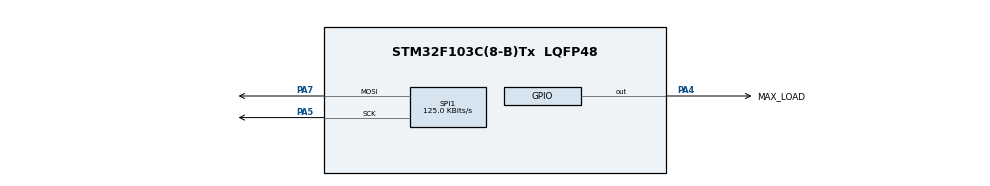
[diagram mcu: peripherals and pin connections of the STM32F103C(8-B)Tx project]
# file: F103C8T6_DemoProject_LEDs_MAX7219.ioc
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Mcu.Family=STM32F1
Mcu.Name=STM32F103C(8-B)Tx
Mcu.Package=LQFP48
NVIC.PriorityGroup=NVIC_PRIORITYGROUP_4
PA13.Mode=Serial_Wire
PA13.Signal=SYS_JTMS-SWDIO
PA14.Mode=Serial_Wire
PA14.Signal=SYS_JTCK-SWCLK
PA4.GPIO_Label=MAX_LOAD
PA4.Signal=GPIO_Output
PA5.Mode=TX_Only_Simplex_Unidirect_Master
PA5.Signal=SPI1_SCK
PA7.Mode=TX_Only_Simplex_Unidirect_Master
PA7.Signal=SPI1_MOSI
ProjectManager.HeapSize=0x200
ProjectManager.StackSize=0x400
ProjectManager.TargetToolchain=STM32CubeIDE
RCC.APB1Freq_Value=8000000
RCC.APB2Freq_Value=8000000
SPI1.BaudRatePrescaler=SPI_BAUDRATEPRESCALER_64
SPI1.CalculateBaudRate=125.0 KBits/s
SPI1.Direction=SPI_DIRECTION_2LINES
SPI1.Mode=SPI_MODE_MASTER
SPI1.VirtualType=VM_MASTER
board=custom

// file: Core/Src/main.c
/* USER CODE BEGIN Header */
/**
  ******************************************************************************
  * @file           : main.c
  * @brief          : Main program body
  ******************************************************************************
  * @attention
  *
  * Copyright (c) 2024 STMicroelectronics.
  * All rights reserved.
  *
  * This software is licensed under terms that can be found in the LICENSE file
  * in the root directory of this software component.
  * If no LICENSE file comes with this software, it is provided AS-IS.
  *
  ******************************************************************************
  */
/* USER CODE END Header */
#include "main.h"
#include "spi.h"
#include "gpio.h"

/* USER CODE BEGIN Includes */
#include "max7219.h"
#include <stdbool.h>
/* USER CODE END Includes */

/* USER CODE BEGIN PD */
#define NUM_LED_PER_ROW 8
/* USER CODE END PD */

/* USER CODE BEGIN PV */
max7219_TypeDef LedDriver;
max7219_LED_TypeDef LedRow1[NUM_LED_PER_ROW];
max7219_LED_TypeDef LedRow2[NUM_LED_PER_ROW];

uint8_t CounterLedsFx = 0;

bool ModeTurnOn = true;
/* USER CODE END PV */

void SystemClock_Config(void);

int main(void)
{

  /* MCU Configuration--------------------------------------------------------*/

  /* Reset of all peripherals, Initializes the Flash interface and the Systick. */
  HAL_Init();

  /* Configure the system clock */
  SystemClock_Config();

  /* Initialize all configured peripherals */
  MX_GPIO_Init();
  MX_SPI1_Init();
  /* USER CODE BEGIN 2 */
  max7219_init_SPI(&LedDriver, &hspi1);
  max7219_init_LoadPin(&LedDriver, GPIOA, GPIO_PIN_4);
  max7219_init_NoDecode(&LedDriver);

  for(uint8_t i = 0; i < NUM_LED_PER_ROW; i++)
  {
    uint8_t DigitRow1 = 0;
    uint8_t DigitRow2 = 1;
    max7219_init_LED(&LedRow1[i], DigitRow1, i);
    max7219_init_LED(&LedRow2[i], DigitRow2, i);
  }

  max7219_turnOff_AllLEDs(&LedDriver);
  /* USER CODE END 2 */

  /* Infinite loop */
  /* USER CODE BEGIN WHILE */
  while (1)
  {
    if(ModeTurnOn == true)
    {
      max7219_turnOn_LED(&LedDriver, &LedRow1[CounterLedsFx]);
      max7219_turnOn_LED(&LedDriver, &LedRow2[CounterLedsFx]);
    }
    else
    {
      max7219_turnOff_LED(&LedDriver, &LedRow1[CounterLedsFx]);
      max7219_turnOff_LED(&LedDriver, &LedRow2[CounterLedsFx]);
    }

    if(CounterLedsFx == (NUM_LED_PER_ROW - 1))
    {
      CounterLedsFx = 0;
      if(ModeTurnOn == true)
      {
        ModeTurnOn = false;
      }
      else
      {
        ModeTurnOn = true;
      }
    }
    else
    {
      CounterLedsFx++;
    }

    uint16_t FxDelay = 500;
    HAL_Delay(FxDelay);
    /* USER CODE END WHILE */

  }
}

void SystemClock_Config(void)
{
  RCC_OscInitTypeDef RCC_OscInitStruct = {0};
  RCC_ClkInitTypeDef RCC_ClkInitStruct = {0};

  /** Initializes the RCC Oscillators according to the specified parameters
  * in the RCC_OscInitTypeDef structure.
  */
  RCC_OscInitStruct.OscillatorType = RCC_OSCILLATORTYPE_HSI;
  RCC_OscInitStruct.HSIState = RCC_HSI_ON;
  RCC_OscInitStruct.HSICalibrationValue = RCC_HSICALIBRATION_DEFAULT;
  RCC_OscInitStruct.PLL.PLLState = RCC_PLL_NONE;
  if (HAL_RCC_OscConfig(&RCC_OscInitStruct) != HAL_OK)
  {
    Error_Handler();
  }

  /** Initializes the CPU, AHB and APB buses clocks
  */
  RCC_ClkInitStruct.ClockType = RCC_CLOCKTYPE_HCLK|RCC_CLOCKTYPE_SYSCLK
                              |RCC_CLOCKTYPE_PCLK1|RCC_CLOCKTYPE_PCLK2;
  RCC_ClkInitStruct.SYSCLKSource = RCC_SYSCLKSOURCE_HSI;
  RCC_ClkInitStruct.AHBCLKDivider = RCC_SYSCLK_DIV1;
  RCC_ClkInitStruct.APB1CLKDivider = RCC_HCLK_DIV1;
  RCC_ClkInitStruct.APB2CLKDivider = RCC_HCLK_DIV1;

  if (HAL_RCC_ClockConfig(&RCC_ClkInitStruct, FLASH_LATENCY_0) != HAL_OK)
  {
    Error_Handler();
  }
}

void Error_Handler(void)
{
  __disable_irq();
  while (1)
  {
  }
}
